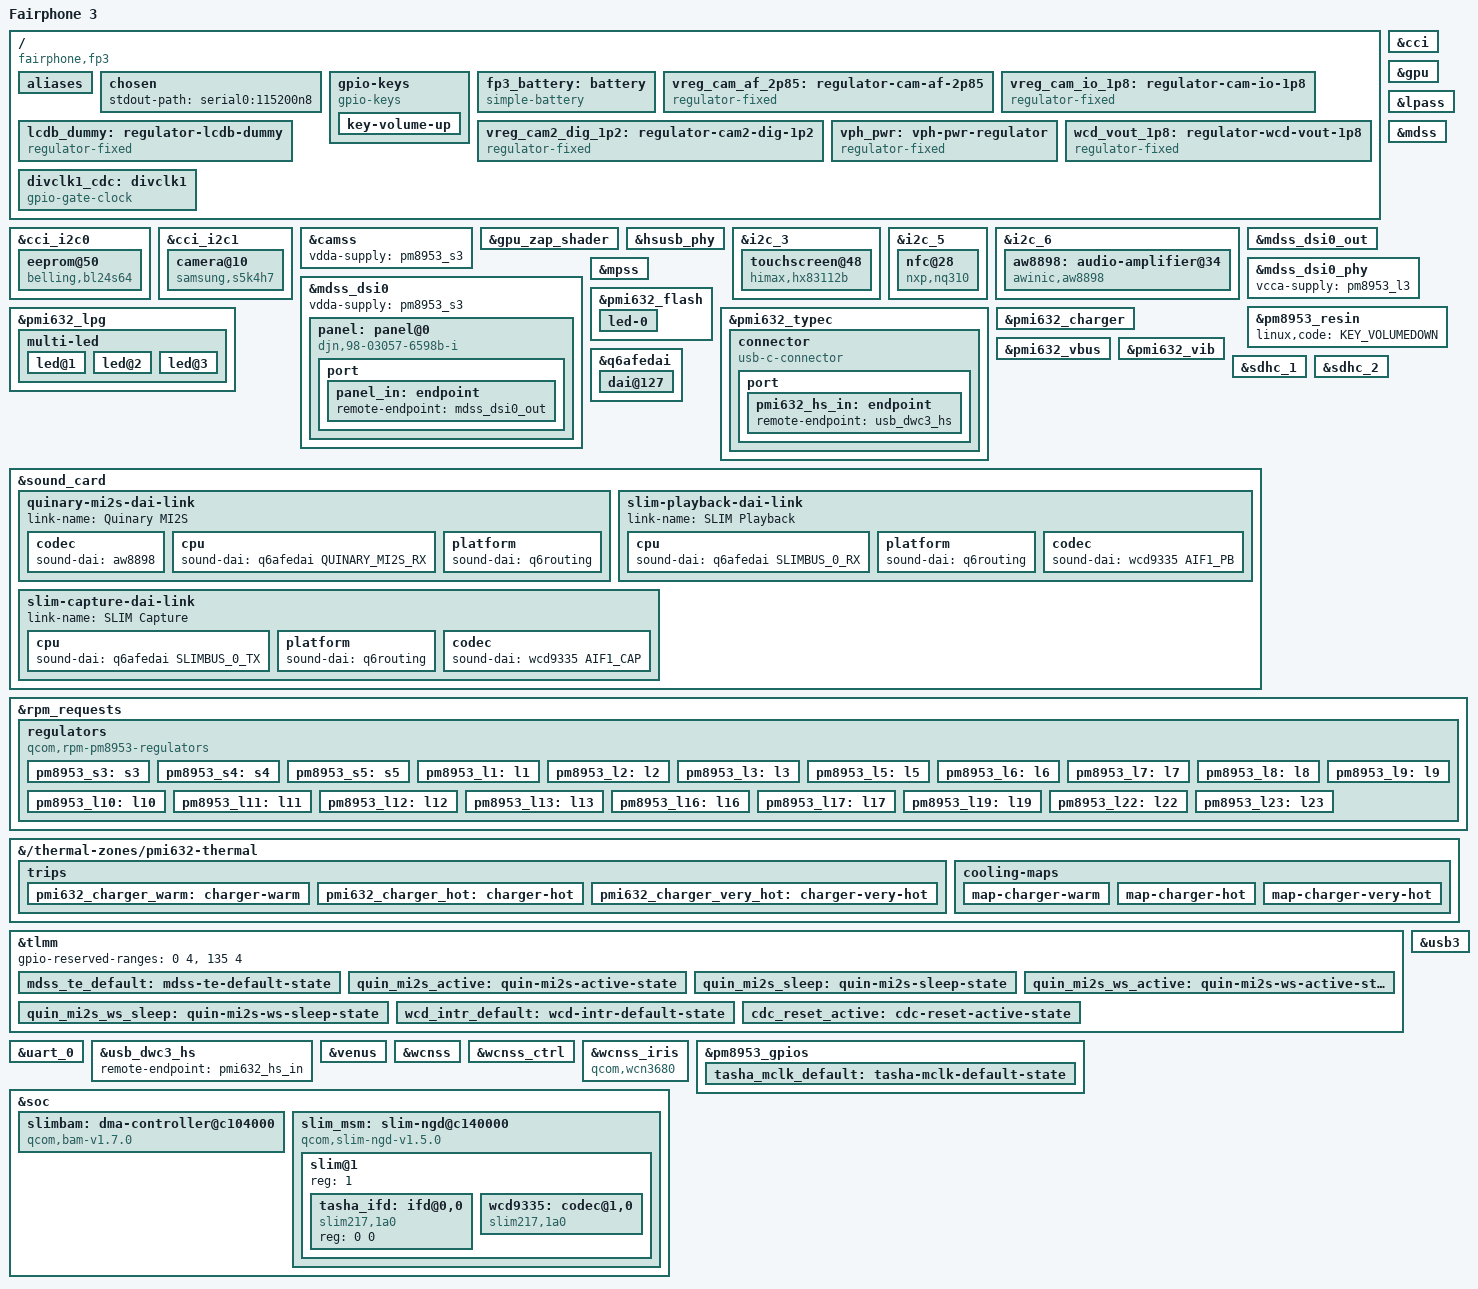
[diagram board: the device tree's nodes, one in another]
// SPDX-License-Identifier: BSD-3-Clause
/*
 * Copyright (c) 2022, Luca Weiss <luca@z3ntu.xyz>
 */
/dts-v1/;

#include <dt-bindings/leds/common.h>
#include <dt-bindings/sound/qcom,wcd9335.h>
#include "sdm632.dtsi"
#include "pm8953.dtsi"
#include "pmi632.dtsi"

/ {
	model = "Fairphone 3";
	compatible = "fairphone,fp3", "qcom,sdm632";
	chassis-type = "handset";
	qcom,msm-id = <349 0>;
	qcom,board-id = <8 0x10000>;

	aliases {
		mmc0 = &sdhc_1;
		mmc1 = &sdhc_2;
		serial0 = &uart_0;
	};

	chosen {
		stdout-path = "serial0:115200n8";
	};

	gpio-keys {
		compatible = "gpio-keys";

		key-volume-up {
			label = "volume_up";
			linux,code = <KEY_VOLUMEUP>;
			gpios = <&tlmm 85 GPIO_ACTIVE_LOW>;
		};
	};

	/*
	 * Battery profile from the Fairphone downstream qg-batterydata.
	 *
	 * The FP3 ships two different 3000 mAh packs, told apart at runtime by
	 * a battery-ID resistor: "Kayo" at 50 kOhm, rated 2.7 A, and "Fuji" at
	 * 10 kOhm, rated 2.0 A. A simple-battery node cannot choose, so this
	 * describes Fuji - the pack in the phone this was developed on, whose
	 * ID resistor measures 10.0 kOhm here and whose downstream stack
	 * reports batt-id 9843 and selects
	 * qg-batterydata-Fuji-3000mah-Jan22th2019-pmi632.
	 *
	 * That means the current below is the pack's full rating, not a
	 * reduction of it. On a phone fitted with the other pack the charger
	 * finds the mismatch through id-resistor-ohms below and falls back to
	 * its conservative default rather than charging a 50 kOhm cell to a
	 * 10 kOhm cell's limits; describing both packs properly needs a
	 * binding for more than one monitored-battery, which does not exist.
	 */
	fp3_battery: battery {
		compatible = "simple-battery";
		voltage-min-design-microvolt = <3400000>;
		voltage-max-design-microvolt = <4390000>;
		/*
		 * 3060 mAh, not the 3000 the pack is sold and named by: it is what
		 * the vendor's own profile declares and what its gauge integrates
		 * against, and this is the capacity the OCV table below was
		 * characterised with, so the two have to agree or a full sweep of
		 * that table does not add up to a full battery.
		 */
		charge-full-design-microamp-hours = <3060000>;
		constant-charge-current-max-microamp = <2000000>;
		constant-charge-voltage-max-microvolt = <4390000>;

		/*
		 * The current at which this pack's charge is over. Both halves
		 * of the vendor's description agree on it: the PMIC node asks
		 * for -100 mA against the charger's ADC, and every battery
		 * profile the tree ships for this phone declares
		 * qcom,chg-term-ua = <100000>.
		 */
		charge-term-current-microamp = <100000>;

		/*
		 * What a loaded terminal voltage has to be corrected by to
		 * recover an open-circuit one. This is what the PMIC's own
		 * gauge measures on this phone: it reports 118 to 126 mOhm
		 * while the vendor stack runs it. The pack profile's nominal
		 * figure is higher, around 166 mOhm, and the two bracket what
		 * a single number can say about a quantity that moves with
		 * temperature and state of charge. It is only ever applied to
		 * samples taken at a current low enough that the difference
		 * between the two ends of that bracket is a few millivolts.
		 */
		factory-internal-resistance-micro-ohms = <120000>;

		/*
		 * The ID resistor this pack presents: 10 kOhm, Fairphone's own
		 * characterisation of this cell, from
		 * qg-batterydata-Fuji-3000mah-Jan22th2019-pmi632.
		 *
		 * It matters because the FP3 also ships a second 3000 mAh pack
		 * ("Kayo", 50 kOhm) rated 2.7 A with its cool band at 20 degC.
		 * Only one battery can be described here, so the charger checks
		 * the resistor before applying any of the limits above.
		 */
		id-resistor-ohms = <10000>;

		/*
		 * Voltage-based fuel gauge: OCV->capacity lookup table.
		 * Extracted from the downstream Fairphone qpnp-qg battery
		 * profile (qg-batterydata-Fuji-3000mah-Jan22th2019-pmi632,
		 * pc-temp-v1-lut, 25 degC column). Values converted from the
		 * downstream 100uV units to microvolts. This is the same OCV
		 * characterisation the downstream QG gauge uses; the mainline
		 * power-supply core interpolates capacity from it.
		 */
		ocv-capacity-celsius = <25>;
		ocv-capacity-table-0 = <4375600 100>, <4353300 98>, <4328800 96>, <4304800 94>,
			<4281100 92>, <4257500 90>, <4234200 88>, <4211000 86>,
			<4188100 84>, <4165400 82>, <4142900 80>, <4121200 78>,
			<4100700 76>, <4080700 74>, <4060200 72>, <4039500 70>,
			<4020600 68>, <4003800 66>, <3988000 64>, <3972500 62>,
			<3957300 60>, <3941900 58>, <3926800 56>, <3910400 54>,
			<3890000 52>, <3868700 50>, <3854500 48>, <3844500 46>,
			<3836800 44>, <3830600 42>, <3825500 40>, <3821400 38>,
			<3818200 36>, <3814800 34>, <3811300 32>, <3807600 30>,
			<3803700 28>, <3799500 26>, <3793600 24>, <3784200 22>,
			<3772700 20>, <3760900 18>, <3747700 16>, <3732200 14>,
			<3717500 12>, <3707900 10>, <3705400 9>, <3703200 8>,
			<3701500 7>, <3698400 6>, <3682100 5>, <3644100 4>,
			<3591600 3>, <3520900 2>, <3415500 1>, <3000000 0>;
	};

	vreg_cam_af_2p85: regulator-cam-af-2p85 {
		compatible = "regulator-fixed";
		regulator-name = "cam_af_2p85";
		regulator-min-microvolt = <2850000>;
		regulator-max-microvolt = <2850000>;

		gpio = <&tlmm 128 GPIO_ACTIVE_HIGH>;
		enable-active-high;

		vin-supply = <&vph_pwr>;
	};

	vreg_cam_io_1p8: regulator-cam-io-1p8 {
		compatible = "regulator-fixed";
		regulator-name = "cam_io_1p8";
		regulator-min-microvolt = <1800000>;
		regulator-max-microvolt = <1800000>;

		gpio = <&tlmm 130 GPIO_ACTIVE_HIGH>;
		enable-active-high;

		vin-supply = <&vph_pwr>;
	};

	vreg_cam2_dig_1p2: regulator-cam2-dig-1p2 {
		compatible = "regulator-fixed";
		regulator-name = "cam2_dig_1p2";
		regulator-min-microvolt = <1200000>;
		regulator-max-microvolt = <1200000>;

		gpio = <&tlmm 46 GPIO_ACTIVE_HIGH>;
		enable-active-high;

		vin-supply = <&vph_pwr>;
	};

	/* Dummy regulator until PMI632 has LCDB VSP/VSN support */
	lcdb_dummy: regulator-lcdb-dummy {
		compatible = "regulator-fixed";
		regulator-name = "lcdb_dummy";
		regulator-min-microvolt = <5500000>;
		regulator-max-microvolt = <5500000>;
	};

	vph_pwr: vph-pwr-regulator {
		compatible = "regulator-fixed";
		regulator-name = "vph_pwr";
		regulator-always-on;
		regulator-boot-on;
	};

	wcd_vout_1p8: regulator-wcd-vout-1p8 {
		compatible = "regulator-fixed";
		regulator-name = "wcd-vout-1p8";
		regulator-min-microvolt = <1800000>;
		regulator-max-microvolt = <1800000>;
		gpio = <&tlmm 50 GPIO_ACTIVE_HIGH>;
		enable-active-high;
	};

	/*
	 * Codec MCLK: PM8953 gpio1-gated clock off RPM DIV_CLK2, exactly as the
	 * downstream FP3 audio config sources it (the same RPM XO-buffer clock,
	 * which downstream labels "clk_div_clk2").
	 */
	divclk1_cdc: divclk1 {
		compatible = "gpio-gate-clock";
		clocks = <&rpmcc RPM_SMD_DIV_CLK2>;
		#clock-cells = <0>;
		enable-gpios = <&pm8953_gpios 1 GPIO_ACTIVE_HIGH>;
		/*
		 * Must be the "default" state: the gpio-gate-clock driver does not
		 * select pinctrl states itself, so only "default" is applied
		 * automatically at probe. With custom "active"/"sleep" names the
		 * gpio1 func1 mux stays UNCLAIMED (pad in its normal-GPIO reset
		 * function) and the divider clock never reaches the WCD9335 MCLK
		 * pin, even though the gate GPIO value is driven. (apq8096-db820c
		 * uses "default" for the same divclk1 mclk.)
		 */
		pinctrl-names = "default";
		pinctrl-0 = <&tasha_mclk_default>;
	};
};

&cci {
	pinctrl-names = "default";
	pinctrl-0 = <&cci0_default>, <&camss_mclk0_default>,
		    <&cci1_default>, <&camss_mclk1_default>;

	status = "okay";
};

&cci_i2c0 {
	/*
	 * The rear camera module sits on this bus, but Fairphone shipped the
	 * phone with two different modules that the firmware cannot tell
	 * apart - IMX363 at 0x1a with an AK7374 actuator at 0x0c, and IMX363
	 * at 0x10 with an LC898217XC at 0x72 - so the sensor and actuator are
	 * described by one overlay per module:
	 * sdm632-fairphone-fp3-rear-camera-ak7374.dtso and
	 * sdm632-fairphone-fp3-rear-camera-lc898217.dtso. The EEPROM is common.
	 */
	eeprom@50 {
		compatible = "belling,bl24s64", "atmel,24c64";
		reg = <0x50>;
		vcc-supply = <&vreg_cam_io_1p8>;
		read-only;
	};
};

&cci_i2c1 {
	/*
	 * The front sensor is described but not yet wired into CAMSS: the
	 * driver identifies the part and registers no subdevice, and an
	 * endpoint whose subdevice never binds would stall the CAMSS async
	 * notifier and take the rear camera down with it. The port belongs
	 * here once this sensor can stream.
	 */
	camera@10 {
		compatible = "samsung,s5k4h7";
		reg = <0x10>;

		/* Front (user-facing) sensor, mounted rotated 270 degrees. */
		orientation = <0>;
		rotation = <270>;

		reset-gpios = <&tlmm 129 GPIO_ACTIVE_LOW>;

		clocks = <&gcc GCC_CAMSS_MCLK1_CLK>;
		assigned-clocks = <&gcc GCC_CAMSS_MCLK1_CLK>;
		assigned-clock-rates = <24000000>;

		vdda-supply = <&pm8953_l22>;		/* 2.8V analog */
		vddio-supply = <&vreg_cam_io_1p8>;	/* 1.8V IO */
		vddd-supply = <&vreg_cam2_dig_1p2>;	/* 1.2V digital core */
	};
};

&camss {
	vdda-supply = <&pm8953_s3>;

	status = "okay";
};

&gpu {
	status = "okay";
};

&gpu_zap_shader {
	firmware-name = "qcom/msm8953/fairphone/fp3/a506_zap.mbn";
};

&hsusb_phy {
	vdd-supply = <&pm8953_l3>;
	vdda-pll-supply = <&pm8953_l7>;
	vdda-phy-dpdm-supply = <&pm8953_l13>;

	status = "okay";
};

&i2c_3 {
	status = "okay";

	touchscreen@48 {
		compatible = "himax,hx83112b";
		reg = <0x48>;
		interrupt-parent = <&tlmm>;
		interrupts = <65 IRQ_TYPE_LEVEL_LOW>;
		touchscreen-size-x = <1080>;
		touchscreen-size-y = <2160>;
		reset-gpios = <&tlmm 64 GPIO_ACTIVE_LOW>;
		panel = <&panel>;

		iovcc-supply = <&pm8953_l6>;
		vdda-supply = <&pm8953_l10>;
	};
};

&i2c_5 {
	status = "okay";

	nfc@28 {
		compatible = "nxp,nq310", "nxp,nxp-nci-i2c";
		reg = <0x28>;

		interrupt-parent = <&tlmm>;
		interrupts = <17 IRQ_TYPE_LEVEL_HIGH>;

		enable-gpios = <&tlmm 16 GPIO_ACTIVE_HIGH>;
		firmware-gpios = <&tlmm 62 GPIO_ACTIVE_HIGH>;
	};
};

&i2c_6 {
	status = "okay";

	aw8898: audio-amplifier@34 {
		compatible = "awinic,aw8898";
		reg = <0x34>;

		reset-gpios = <&tlmm 21 GPIO_ACTIVE_LOW>;
		interrupts-extended = <&tlmm 20 IRQ_TYPE_LEVEL_HIGH>;

		dvdd-supply = <&pm8953_l5>;
		vddio-supply = <&pm8953_l5>;
		vdd-supply = <&vph_pwr>;

		#sound-dai-cells = <0>;
	};

	/* Fairphone 3+ only: Speaker amp TAS2557 @ 4c */
};

&lpass {
	firmware-name = "qcom/msm8953/fairphone/fp3/adsp.mbn";

	status = "okay";
};

&mdss {
	status = "okay";
};

&mdss_dsi0 {
	vdda-supply = <&pm8953_s3>;
	status = "okay";

	panel: panel@0 {
		compatible = "djn,98-03057-6598b-i";
		reg = <0>;

		reset-gpios = <&tlmm 61 GPIO_ACTIVE_LOW>;

		iovcc-supply = <&pm8953_l6>;
		vsn-supply = <&lcdb_dummy>;
		vsp-supply = <&lcdb_dummy>;

		pinctrl-0 = <&mdss_te_default>;
		pinctrl-names = "default";

		port {
			panel_in: endpoint {
				remote-endpoint = <&mdss_dsi0_out>;
			};
		};
	};
};

&mdss_dsi0_out {
	data-lanes = <0 1 2 3>;
	remote-endpoint = <&panel_in>;
};

&mdss_dsi0_phy {
	vcca-supply = <&pm8953_l3>;
	status = "okay";
};

&mpss {
	firmware-name = "qcom/msm8953/fairphone/fp3/mba.mbn",
			"qcom/msm8953/fairphone/fp3/modem.mbn";
	pll-supply = <&pm8953_l7>;

	status = "okay";
};

&pm8953_resin {
	linux,code = <KEY_VOLUMEDOWN>;
	status = "okay";
};

&pmi632_flash {
	status = "okay";

	led-0 {
		function = LED_FUNCTION_FLASH;
		color = <LED_COLOR_ID_WHITE>;
		led-sources = <1>, <2>;
		led-max-microamp = <600000>;
		flash-max-microamp = <2000000>;
		flash-max-timeout-us = <1280000>;
	};
};

&pmi632_lpg {
	status = "okay";

	multi-led {
		color = <LED_COLOR_ID_RGB>;
		function = LED_FUNCTION_STATUS;

		#address-cells = <1>;
		#size-cells = <0>;

		led@1 {
			reg = <1>;
			color = <LED_COLOR_ID_RED>;
		};

		led@2 {
			reg = <2>;
			color = <LED_COLOR_ID_GREEN>;
		};

		led@3 {
			reg = <3>;
			color = <LED_COLOR_ID_BLUE>;
		};
	};
};

&pmi632_typec {
	status = "okay";

	connector {
		compatible = "usb-c-connector";

		power-role = "dual";
		data-role = "dual";
		self-powered;

		typec-power-opmode = "default";
		pd-disable;

		port {
			pmi632_hs_in: endpoint {
				remote-endpoint = <&usb_dwc3_hs>;
			};
		};
	};
};

&pmi632_charger {
	monitored-battery = <&fp3_battery>;

	/*
	 * Which PMIC pull-up the bat_id channel switches in, so the charger can
	 * turn the divider reading back into the pack's ID resistance. It
	 * follows from the channel chosen in pmi632.dtsi, but nothing in the
	 * ADC consumer interface exposes that, so the board states it.
	 */
	qcom,batt-id-pullup-ohms = <100000>;

	/*
	 * The voltage at which a finished charge is started again. Fairphone's
	 * own pmi632 node carries this as qcom,auto-recharge-vbat-mv = <4300>,
	 * under a dated vendor comment naming the voltage it wants, with the
	 * state-of-charge alternative commented out beside it. Ninety
	 * millivolts below the float, so a pack is not cycled for the few
	 * millivolts it relaxes by.
	 */
	qcom,auto-recharge-microvolt = <4300000>;

	/*
	 * Hard limits at 0 and 55 degC, soft limits at 15 and 45, and the
	 * currents to be left with in the two soft zones - Fairphone's
	 * characterisation of the Fuji pack, from
	 * qg-batterydata-Fuji-3000mah-Jan22th2019-pmi632, verified against a
	 * phone running the vendor stack, which programs the same four.
	 *
	 * These live on the charger and not on the battery because they are raw
	 * BAT_THERM ADC codes: which code a temperature produces depends on
	 * this PMIC's ADC full scale and on the pull-up above as much as on the
	 * cell, so a code cannot travel with a pack.
	 */
	qcom,jeita-hard-thresholds = <0x5675 0x1987>;
	qcom,jeita-soft-thresholds = <0x44ff 0x2204>;
	qcom,jeita-soft-fcc-microamp = <600000 1000000>;

	/* Downstream's mitigation table, minus its repeated last entry. */
	qcom,thermal-mitigation = <2000000 1500000 1000000 500000>;

	/*
	 * No qcom,connector-internal-pull-kohm here, although the downstream
	 * device tree gives 100 for this PMIC and the charger can regulate its
	 * input current against a connector thermistor.
	 *
	 * Enabling it here stopped charging outright: the charger reported
	 * TEMP_ABOVE_RANGE and TLIM in MISC_TEMP_RANGE_STATUS while
	 * MISC_DIE_TEMP_STATUS stayed clear, so it was the connector reading,
	 * and it read hot on a phone lying idle at 32 degrees. The input limit
	 * went to zero - the Type-C block saw its 5 V, the charger's USBIN saw
	 * nothing, and the battery discharged with the cable in.
	 *
	 * The thermistor is not the problem, though, and an earlier version of
	 * this comment wrongly said the board does not populate one. The vendor
	 * stack on the same phone runs with BATIF_ADC_CHANNEL_EN = 0xd5 and
	 * MISC_THERMREG_SRC_CFG = 0x13 - connector channel and regulation
	 * source both on - and reads TEMP_RANGE_STATUS = 0x02, in range. So the
	 * part is there and works; something else in the ADC configuration is
	 * missing here. The candidates, all in BATIF and none of them named by
	 * this driver, differ between the two: 0x12e2 (0x43 here, 0x07 there),
	 * 0x12e5 (0x42/0x46), 0x12ea (0x00/0x02), 0x12ed (0x94/0x82).
	 *
	 * Until that is understood, leave the property out rather than ship a
	 * board that will not charge.
	 */

	status = "okay";
};

&pmi632_vbus {
	regulator-min-microamp = <500000>;
	regulator-max-microamp = <1000000>;
	status = "okay";
};

&pmi632_vib {
	status = "okay";
};

&q6afedai {
	dai@127 {
		reg = <QUINARY_MI2S_RX>;
		qcom,sd-lines = <0 1>;
	};
};

&sdhc_1 {
	vmmc-supply = <&pm8953_l8>;
	vqmmc-supply = <&pm8953_l5>;

	status = "okay";
};

&sdhc_2 {
	vmmc-supply = <&pm8953_l11>;
	vqmmc-supply = <&pm8953_l12>;

	cd-gpios = <&tlmm 133 GPIO_ACTIVE_LOW>;

	status = "okay";
};

&sound_card {
	model = "Fairphone 3";

	pinctrl-0 = <&quin_mi2s_active>, <&quin_mi2s_ws_active>;
	pinctrl-1 = <&quin_mi2s_sleep>, <&quin_mi2s_ws_sleep>;
	pinctrl-names = "default",
			"sleep";

	status = "okay";

	/*
	 * Replace the inherited PM8953-codec routing: the WCD9335's MCLK supply
	 * widget has no in-codec route, so the board must pull it in. RX_BIAS is
	 * a dependency of every RX interpolator DAC, so "RX_BIAS" -> "MCLK" keeps
	 * the external MCLK (divclk1) enabled for the whole playback path.
	 * (Same single route every wcd9335 board uses, e.g. apq8096-db820c.)
	 */
	/*
	 * The analog mics need their bias supply routed in the same way: the
	 * WCD9335 "MIC BIAS<n>" widgets are supplies with no in-codec route, so
	 * without these the capsule is unpowered and capture records ~digital
	 * silence. Mapping mirrors the downstream FP3 audio DT: the handset
	 * (main) mic is AMIC5 on MIC BIAS3, the headset mic is AMIC2 on
	 * MIC BIAS2. AMIC1 is not connected on this board.
	 *
	 * Only the supply->input direction is listed. The downstream DT also
	 * carries the reverse "MIC BIAS<n>" -> "<name> Mic" pairs, but modern
	 * ASoC rejects connecting a non-supply widget into a supply widget,
	 * which fails the whole card probe.
	 */
	/*
	 * MCLK has no in-codec routes either, so every path that needs it has
	 * to pull it up from here. Wiring it through RX_BIAS alone leaves the
	 * capture path unclocked and the decimators emit zeroes unless a
	 * playback stream happens to be running at the same time.
	 */
	audio-routing = "RX_BIAS", "MCLK",
			"AMIC2", "MCLK",
			"AMIC5", "MCLK",
			"AMIC5", "MIC BIAS3",
			"AMIC2", "MIC BIAS2",
			/*
			 * The digital mics are supplies-with-no-route as well, and
			 * their clock is divided down from MCLK, so they need both.
			 * Bias mapping mirrors the downstream FP3 audio DT.
			 */
			"DMIC0", "MCLK",
			"DMIC1", "MCLK",
			"DMIC2", "MCLK",
			"DMIC3", "MCLK",
			"DMIC4", "MCLK",
			"DMIC5", "MCLK",
			/*
			 * A DMIC widget is an ADC, not an input, so DAPM will not power
			 * it from a supply alone - it needs a source endpoint. Downstream
			 * gets that from the reverse "MIC BIAS<n>" -> "Digital Mic<n>"
			 * pair, which modern ASoC rejects, so wire the mic widget
			 * straight to the DMIC instead.
			 */
			"DMIC0", "Digital Mic0",
			"DMIC1", "Digital Mic1",
			"DMIC2", "Digital Mic2",
			"DMIC3", "Digital Mic3",
			"DMIC4", "Digital Mic4",
			"DMIC5", "Digital Mic5",
			"DMIC0", "MIC BIAS1",
			"DMIC1", "MIC BIAS1",
			"DMIC2", "MIC BIAS3",
			"DMIC3", "MIC BIAS3",
			"DMIC4", "MIC BIAS4",
			"DMIC5", "MIC BIAS4";
	/delete-node/ primary-mi2s-dai-link;
	/delete-node/ tertiary-mi2s-dai-link;

	quinary-mi2s-dai-link {
		link-name = "Quinary MI2S";

		codec {
			sound-dai = <&aw8898>;
		};

		cpu {
			sound-dai = <&q6afedai QUINARY_MI2S_RX>;
		};

		platform {
			sound-dai = <&q6routing>;
		};
	};

	/* WCD9335 over SLIMbus: earpiece/headset playback + mic capture */
	slim-playback-dai-link {
		link-name = "SLIM Playback";

		cpu {
			sound-dai = <&q6afedai SLIMBUS_0_RX>;
		};

		platform {
			sound-dai = <&q6routing>;
		};

		codec {
			sound-dai = <&wcd9335 AIF1_PB>;
		};
	};

	slim-capture-dai-link {
		link-name = "SLIM Capture";

		cpu {
			sound-dai = <&q6afedai SLIMBUS_0_TX>;
		};

		platform {
			sound-dai = <&q6routing>;
		};

		codec {
			sound-dai = <&wcd9335 AIF1_CAP>;
		};
	};
};

&rpm_requests {
	regulators {
		compatible = "qcom,rpm-pm8953-regulators";

		vdd_l1-supply = <&pm8953_s3>;
		vdd_l2_l3-supply = <&pm8953_s3>;
		vdd_l4_l5_l6_l7_l16_l19-supply = <&pm8953_s4>;
		vdd_l8_l11_l12_l13_l14_l15-supply = <&vph_pwr>;
		vdd_l9_l10_l17_l18_l22-supply = <&vph_pwr>;

		pm8953_s3: s3 {
			regulator-min-microvolt = <984000>;
			regulator-max-microvolt = <1240000>;
		};

		pm8953_s4: s4 {
			regulator-min-microvolt = <1036000>;
			regulator-max-microvolt = <2040000>;
		};

		pm8953_s5: s5 {
			regulator-min-microvolt = <1036000>;
			regulator-max-microvolt = <2040000>;
		};

		pm8953_l1: l1 {
			regulator-min-microvolt = <975000>;
			regulator-max-microvolt = <1050000>;
		};

		pm8953_l2: l2 {
			regulator-min-microvolt = <975000>;
			regulator-max-microvolt = <1175000>;
		};

		pm8953_l3: l3 {
			regulator-min-microvolt = <925000>;
			regulator-max-microvolt = <925000>;
		};

		pm8953_l5: l5 {
			regulator-min-microvolt = <1800000>;
			regulator-max-microvolt = <1800000>;
		};

		pm8953_l6: l6 {
			regulator-min-microvolt = <1800000>;
			regulator-max-microvolt = <1800000>;
		};

		pm8953_l7: l7 {
			regulator-min-microvolt = <1800000>;
			regulator-max-microvolt = <1900000>;
		};

		pm8953_l8: l8 {
			regulator-min-microvolt = <2900000>;
			regulator-max-microvolt = <2900000>;
		};

		pm8953_l9: l9 {
			regulator-min-microvolt = <3000000>;
			regulator-max-microvolt = <3300000>;
		};

		pm8953_l10: l10 {
			regulator-min-microvolt = <2800000>;
			regulator-max-microvolt = <3000000>;
		};

		pm8953_l11: l11 {
			regulator-min-microvolt = <2950000>;
			regulator-max-microvolt = <2950000>;
		};

		pm8953_l12: l12 {
			regulator-min-microvolt = <1800000>;
			regulator-max-microvolt = <2950000>;
		};

		pm8953_l13: l13 {
			regulator-min-microvolt = <3125000>;
			regulator-max-microvolt = <3125000>;
		};

		pm8953_l16: l16 {
			regulator-min-microvolt = <1800000>;
			regulator-max-microvolt = <1800000>;
		};

		pm8953_l17: l17 {
			regulator-min-microvolt = <2850000>;
			regulator-max-microvolt = <2850000>;
		};

		pm8953_l19: l19 {
			regulator-min-microvolt = <1200000>;
			regulator-max-microvolt = <1350000>;
		};

		pm8953_l22: l22 {
			regulator-min-microvolt = <2800000>;
			regulator-max-microvolt = <2800000>;
		};

		pm8953_l23: l23 {
			regulator-min-microvolt = <975000>;
			regulator-max-microvolt = <1225000>;
		};
	};
};

/*
 * Throttle charging on the charger's own die temperature. Downstream calls
 * this qcom,hw-die-temp-mitigation and drives it from a userspace thermal
 * daemon; here the PMIC's temperature zone drives it directly.
 *
 * The trips are ours. The zone already ends at the PMI632's own alarms, which
 * start at 95 degC, so these sit below that with room to act: measured on this
 * board the die idles at 37 degC, and the three steps taper the charge current
 * before the hardware has to.
 */
&{/thermal-zones/pmi632-thermal} {
	trips {
		pmi632_charger_warm: charger-warm {
			temperature = <70000>;
			hysteresis = <2000>;
			type = "passive";
		};

		pmi632_charger_hot: charger-hot {
			temperature = <80000>;
			hysteresis = <2000>;
			type = "passive";
		};

		pmi632_charger_very_hot: charger-very-hot {
			temperature = <90000>;
			hysteresis = <2000>;
			type = "passive";
		};
	};

	cooling-maps {
		map-charger-warm {
			trip = <&pmi632_charger_warm>;
			cooling-device = <&pmi632_charger 1 1>;
		};

		map-charger-hot {
			trip = <&pmi632_charger_hot>;
			cooling-device = <&pmi632_charger 2 2>;
		};

		map-charger-very-hot {
			trip = <&pmi632_charger_very_hot>;
			cooling-device = <&pmi632_charger 3 3>;
		};
	};
};

&tlmm {
	/*
	 * 0-3: unused but protected by TZ
	 * 135-138: fingerprint reader (SPI)
	 */
	gpio-reserved-ranges = <0 4>, <135 4>;

	mdss_te_default: mdss-te-default-state {
		pins = "gpio24";
		function = "mdp_vsync";
		drive-strength = <2>;
		bias-pull-down;
	};

	quin_mi2s_active: quin-mi2s-active-state {
		pins = "gpio88", "gpio91", "gpio93";
		function = "pri_mi2s";
		drive-strength = <8>;
	};

	quin_mi2s_sleep: quin-mi2s-sleep-state {
		pins = "gpio88", "gpio91", "gpio93";
		function = "pri_mi2s";
		drive-strength = <2>;
		bias-pull-down;
	};

	quin_mi2s_ws_active: quin-mi2s-ws-active-state {
		pins = "gpio92";
		function = "pri_mi2s_ws";
		drive-strength = <8>;
	};

	quin_mi2s_ws_sleep: quin-mi2s-ws-sleep-state {
		pins = "gpio92";
		function = "pri_mi2s_ws";
		drive-strength = <2>;
		bias-pull-down;
	};
};

&uart_0 {
	status = "okay";
};

&usb3 {
	status = "okay";
};

&usb_dwc3_hs {
	remote-endpoint = <&pmi632_hs_in>;
};

&venus {
	firmware-name = "qcom/msm8953/fairphone/fp3/venus.mbn";

	status = "okay";
};

&wcnss {
	firmware-name = "qcom/msm8953/fairphone/fp3/wcnss.mbn";
	vddpx-supply = <&pm8953_l5>;

	status = "okay";
};

&wcnss_ctrl {
	firmware-name = "qcom/msm8953/fairphone/fp3/WCNSS_qcom_wlan_nv.bin";
};

&wcnss_iris {
	compatible = "qcom,wcn3680";

	vddxo-supply = <&pm8953_l7>;
	vddrfa-supply = <&pm8953_l19>;
	vddpa-supply = <&pm8953_l9>;
	vdddig-supply = <&pm8953_l5>;
};

/*
 * Fairphone 3 audio: WCD9335 codec over SLIMbus.
 *
 * The SLIMbus NGD controller uses the standard qcom,slim-ngd-v1.5.0 binding
 * (defined for MSM8996; the msm8953 NGD is the same hardware generation). The
 * FP3-specific node instantiation below -- the NGD/BAM addresses and the
 * WCD9335 codec setup (reset/interrupt pinctrl, MCLK, regulators, channels) --
 * is adapted from Bert Karwatzki's working Fairphone 3 configuration; no other
 * msm8953 board in-tree instantiates the SLIMbus NGD.
 * Link: https://lkml.iu.edu/hypermail/linux/kernel/2502.1/00985.html
 *
 * These plug into the msm8953 q6afe / q6routing / sound-card infrastructure in
 * msm8953.dtsi (authored by Trịnh Duy Mạnh); those nodes are only referenced
 * here by label, their authorship preserved in that file's history.
 */
&tlmm {
	wcd_intr_default: wcd-intr-default-state {
		pins = "gpio73";
		function = "gpio";
		drive-strength = <2>;
		bias-pull-down;
	};

	cdc_reset_active: cdc-reset-active-state {
		pins = "gpio67";
		function = "gpio";
		drive-strength = <16>;
		bias-pull-down;
		output-high;
	};
};

&pm8953_gpios {
	/*
	 * Keep this to the bare mux (function "func1" routes RPM DIV_CLK2 to
	 * the pad, i.e. PMIC gpio source-select 2, matching the downstream FP3
	 * codec MCLK). Adding drive-strength/bias/output pinconf here makes the
	 * "default" state fail to apply on this PMIC, which aborts the
	 * gpio-gate-clock probe so no MCLK is produced at all.
	 */
	tasha_mclk_default: tasha-mclk-default-state {
		pins = "gpio1";
		function = "func1";
		power-source = <0>;
	};
};

&soc {
	slimbam: dma-controller@c104000 {
		compatible = "qcom,bam-v1.7.0";
		qcom,controlled-remotely;
		reg = <0x0c104000 0x2a000>;
		interrupts = <GIC_SPI 180 IRQ_TYPE_LEVEL_HIGH>;
		#dma-cells = <1>;
		qcom,ee = <1>;
		qcom,num-ees = <3>;
		num-channels = <23>;
	};

	slim_msm: slim-ngd@c140000 {
		compatible = "qcom,slim-ngd-v1.5.0";
		reg = <0x0c140000 0x2c000>;
		interrupts = <GIC_SPI 163 IRQ_TYPE_LEVEL_HIGH>;
		dmas = <&slimbam 3>, <&slimbam 4>;
		dma-names = "rx", "tx";
		#address-cells = <1>;
		#size-cells = <0>;
		status = "okay";

		slim@1 {
			reg = <1>;
			#address-cells = <2>;
			#size-cells = <0>;

			tasha_ifd: ifd@0,0 {
				compatible = "slim217,1a0";
				reg = <0 0>;
			};

			wcd9335: codec@1,0 {
				compatible = "slim217,1a0";
				reg = <1 0>;
				slim-ifc-dev = <&tasha_ifd>;
				#sound-dai-cells = <1>;
				interrupt-parent = <&tlmm>;
				interrupts = <73 IRQ_TYPE_LEVEL_HIGH>,
					     <74 IRQ_TYPE_LEVEL_HIGH>;
				interrupt-names = "intr1", "intr2";
				interrupt-controller;
				#interrupt-cells = <1>;
				reset-gpios = <&tlmm 67 GPIO_ACTIVE_LOW>;
				pinctrl-0 = <&cdc_reset_active &wcd_intr_default>;
				pinctrl-names = "default";
				clock-names = "mclk", "slimbus";
				clocks = <&divclk1_cdc>, <&rpmcc RPM_SMD_DIV_CLK2>;
				vdd-buck-supply = <&wcd_vout_1p8>;
				vdd-buck-sido-supply = <&wcd_vout_1p8>;
				vdd-tx-supply = <&wcd_vout_1p8>;
				vdd-rx-supply = <&wcd_vout_1p8>;
				vdd-io-supply = <&wcd_vout_1p8>;
				vdd-micbias-supply = <&vph_pwr>;

				/* Downstream biases the headset/analog mic rail higher. */
				qcom,micbias1-microvolt = <1800000>;
				qcom,micbias2-microvolt = <2800000>;
				qcom,micbias3-microvolt = <1800000>;
				qcom,micbias4-microvolt = <1800000>;

				/* Digital mic capsules run at 2.4 MHz on this board. */
				qcom,dmic-sample-rate = <2400000>;

				/*
				 * Headset (MBHC) button thresholds - the common
				 * Qualcomm reference values.
				 */
				qcom,mbhc-buttons-vthreshold-microvolt =
					<75000 150000 237000 450000 500000
					 500000 500000 500000>;
			};
		};
	};
};
